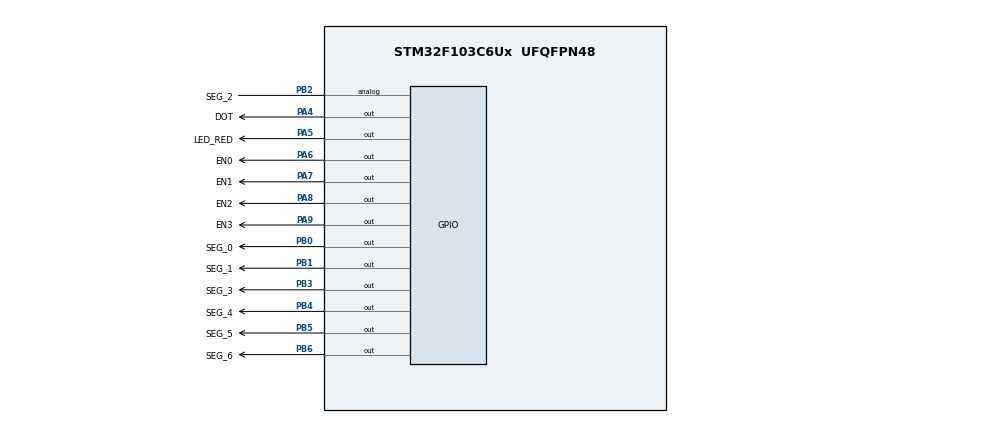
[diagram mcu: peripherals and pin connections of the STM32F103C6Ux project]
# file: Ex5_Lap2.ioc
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Mcu.Family=STM32F1
Mcu.Name=STM32F103C6Ux
Mcu.Package=UFQFPN48
NVIC.PriorityGroup=NVIC_PRIORITYGROUP_4
NVIC.TIM2_IRQn=true\:0\:0\:false\:false\:true\:true\:true
PA4.GPIO_Label=DOT
PA4.Signal=GPIO_Output
PA5.GPIO_Label=LED_RED
PA5.Signal=GPIO_Output
PA6.GPIO_Label=EN0
PA6.Signal=GPIO_Output
PA7.GPIO_Label=EN1
PA7.Signal=GPIO_Output
PA8.GPIO_Label=EN2
PA8.Signal=GPIO_Output
PA9.GPIO_Label=EN3
PA9.Signal=GPIO_Output
PB0.GPIO_Label=SEG_0
PB0.Signal=GPIO_Output
PB1.GPIO_Label=SEG_1
PB1.Signal=GPIO_Output
PB2.GPIO_Label=SEG_2
PB2.Signal=GPIO_Analog
PB3.GPIO_Label=SEG_3
PB3.Signal=GPIO_Output
PB4.GPIO_Label=SEG_4
PB4.Signal=GPIO_Output
PB5.GPIO_Label=SEG_5
PB5.Signal=GPIO_Output
PB6.GPIO_Label=SEG_6
PB6.Signal=GPIO_Output
ProjectManager.HeapSize=0x200
ProjectManager.StackSize=0x400
ProjectManager.TargetToolchain=STM32CubeIDE
RCC.APB1Freq_Value=8000000
RCC.APB2Freq_Value=8000000
TIM2.Period=9
TIM2.Prescaler=7999
VP_SYS_VS_ND.Mode=No_Debug
VP_TIM2_VS_ClockSourceINT.Mode=Internal
board=custom

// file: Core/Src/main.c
/* USER CODE BEGIN Header */
/**
  ******************************************************************************
  * @file           : main.c
  * @brief          : Main program body
  ******************************************************************************
  * @attention
  *
  * <h2><center>&copy; Copyright (c) 2022 STMicroelectronics.
  * All rights reserved.</center></h2>
  *
  * This software component is licensed by ST under BSD 3-Clause license,
  * the "License"; You may not use this file except in compliance with the
  * License. You may obtain a copy of the License at:
  *                        opensource.org/licenses/BSD-3-Clause
  *
  ******************************************************************************
  */
/* USER CODE END Header */
#include "main.h"

TIM_HandleTypeDef htim2;

void SystemClock_Config(void);
static void MX_GPIO_Init(void);
static void MX_TIM2_Init(void);

int NUM[10][7]= {
	{0,0,0,0,0,0,1}, //0
	{1,0,0,1,1,1,1}, //1
	{0,0,1,0,0,1,0}, //2
	{0,0,0,0,1,1,0}, //3
	{1,0,0,1,1,0,0}, //4
	{0,1,0,0,1,0,0}, //5
	{0,1,0,0,0,0,0}, //6
	{0,0,0,1,1,1,1}, //7
	{0,0,0,0,0,0,0}, //8
	{0,0,0,0,1,0,0}  //9
};
void display7SEG(int num){
	HAL_GPIO_WritePin(SEG_0_GPIO_Port, SEG_0_Pin, NUM[num][0] );// tin hieu thanh 0
	HAL_GPIO_WritePin(SEG_1_GPIO_Port, SEG_1_Pin, NUM[num][1] );// tin hieu thanh 1
	HAL_GPIO_WritePin(SEG_2_GPIO_Port, SEG_2_Pin, NUM[num][2] );// tin hieu thanh 2
	HAL_GPIO_WritePin(SEG_3_GPIO_Port, SEG_3_Pin, NUM[num][3] );// tin hieu thanh 3
	HAL_GPIO_WritePin(SEG_4_GPIO_Port, SEG_4_Pin, NUM[num][4] );// tin hieu thanh 4
	HAL_GPIO_WritePin(SEG_5_GPIO_Port, SEG_5_Pin, NUM[num][5] );// tin hieu thanh 5
	HAL_GPIO_WritePin(SEG_6_GPIO_Port, SEG_6_Pin, NUM[num][6] );// tin hieu thanh 6
}

int counter = 25;
const int MAX_LED = 4;
int index_led = 0;
int led_buffer [4] = {1 , 2 , 3 , 4};

void updateClockBuffer(int hour, int minute){
 	// update hour
 	if(hour < 10){
 		led_buffer[0]= 0;
 		led_buffer[1]= hour;
 	}
 	else if(hour < 20 && hour>10){
 		led_buffer[0]= 1;
 		led_buffer[1]= hour%10;
 	}
 	else{
 	    led_buffer[0]= 2;
 		led_buffer[1]= hour%20;
 	}
 	// update minute
 	if(minute<10){
 		led_buffer[2]= 0;
 		led_buffer[3]= minute;
 	}
 	else if(minute>=10&& minute<20){
 		led_buffer[2]= 1;
 		led_buffer[3]= minute%10;
 	}
 	else if(minute>=20&& minute<30){
 		led_buffer[2]= 2;
 		led_buffer[3]= minute%20;
 	}
 	else if(minute>=30&& minute<40){
 		led_buffer[2]= 3;
 		led_buffer[3]=  minute%30;
 	}
 	else if(minute>=40&& minute<50){
 		led_buffer[2]= 4;
 		led_buffer[3]= minute%40;
 	}
 	else if(minute>=50&& minute<60){
 		led_buffer[2]= 5;
 		led_buffer[3]= minute%50;
 	}
 	else{
 		led_buffer[2]= 6;
 		led_buffer[3]= 0;
 	}
 }
void led_on(int index_led){
switch( index_led){
		case 0:
			HAL_GPIO_WritePin(EN0_GPIO_Port, EN0_Pin, RESET);
			HAL_GPIO_WritePin(EN1_GPIO_Port, EN1_Pin, SET);
			HAL_GPIO_WritePin(EN2_GPIO_Port, EN2_Pin, SET);
			HAL_GPIO_WritePin(EN3_GPIO_Port, EN3_Pin, SET);
		break;

		case 1:
			HAL_GPIO_WritePin(EN0_GPIO_Port, EN0_Pin, SET);
			HAL_GPIO_WritePin(EN1_GPIO_Port, EN1_Pin, RESET);
			HAL_GPIO_WritePin(EN2_GPIO_Port, EN2_Pin, SET);
			HAL_GPIO_WritePin(EN3_GPIO_Port, EN3_Pin, SET);
		break;

		case 2:
			HAL_GPIO_WritePin(EN0_GPIO_Port, EN0_Pin, SET);
			HAL_GPIO_WritePin(EN1_GPIO_Port, EN1_Pin, SET);
			HAL_GPIO_WritePin(EN2_GPIO_Port, EN2_Pin, RESET);
			HAL_GPIO_WritePin(EN3_GPIO_Port, EN3_Pin, SET);
		break;

		case 3:
			HAL_GPIO_WritePin(EN0_GPIO_Port, EN0_Pin, SET);
			HAL_GPIO_WritePin(EN1_GPIO_Port, EN1_Pin, SET);
			HAL_GPIO_WritePin(EN2_GPIO_Port, EN2_Pin, SET);
			HAL_GPIO_WritePin(EN3_GPIO_Port, EN3_Pin, RESET);
		break;
	}
}
void update7SEG ( int index_led) {
switch ( index_led ) {
		case 0:
		// Display the first 7 SEG
			led_on(0);
			display7SEG(led_buffer[0]);
		break ;
		case 1:
		// Display the second 7 SEG
			led_on(1);
			display7SEG(led_buffer[1]);
		break ;
		case 2:
		// Display the third 7 SEG
			led_on(2);
			display7SEG(led_buffer[2]);
		break ;
		case 3:
		// Display the forth 7 SEG
			led_on(3);
			display7SEG(led_buffer[3]);
		break ;
		default :
		break ;
}
}

TIM_HandleTypeDef htim2;

int main(void)
{

  /* MCU Configuration--------------------------------------------------------*/

  /* Reset of all peripherals, Initializes the Flash interface and the Systick. */
  HAL_Init();

  /* Configure the system clock */
  SystemClock_Config();

  /* Initialize all configured peripherals */
  MX_GPIO_Init();
  MX_TIM2_Init();
  HAL_TIM_Base_Start_IT (& htim2 ) ;

  /* Infinite loop */
  /* USER CODE BEGIN WHILE */
  	int hour = 15 , minute = 8 , second = 50;
    while (1)
    {
    /* USER CODE END WHILE */
    	 second ++;
    		   if ( second >= 60) {
    			   second = 0;
    			   minute++;
    		   }
    		   if( minute >= 60) {
    			   minute = 0;
    			   hour++;
    		   }
    		   if( hour >=24) {
    			   hour = 0;
    		   }
    		   updateClockBuffer(hour, minute);
    		   HAL_Delay (1000);
  }
}

void SystemClock_Config(void)
{
  RCC_OscInitTypeDef RCC_OscInitStruct = {0};
  RCC_ClkInitTypeDef RCC_ClkInitStruct = {0};

  /** Initializes the RCC Oscillators according to the specified parameters
  * in the RCC_OscInitTypeDef structure.
  */
  RCC_OscInitStruct.OscillatorType = RCC_OSCILLATORTYPE_HSI;
  RCC_OscInitStruct.HSIState = RCC_HSI_ON;
  RCC_OscInitStruct.HSICalibrationValue = RCC_HSICALIBRATION_DEFAULT;
  RCC_OscInitStruct.PLL.PLLState = RCC_PLL_NONE;
  if (HAL_RCC_OscConfig(&RCC_OscInitStruct) != HAL_OK)
  {
    Error_Handler();
  }
  /** Initializes the CPU, AHB and APB buses clocks
  */
  RCC_ClkInitStruct.ClockType = RCC_CLOCKTYPE_HCLK|RCC_CLOCKTYPE_SYSCLK
                              |RCC_CLOCKTYPE_PCLK1|RCC_CLOCKTYPE_PCLK2;
  RCC_ClkInitStruct.SYSCLKSource = RCC_SYSCLKSOURCE_HSI;
  RCC_ClkInitStruct.AHBCLKDivider = RCC_SYSCLK_DIV1;
  RCC_ClkInitStruct.APB1CLKDivider = RCC_HCLK_DIV1;
  RCC_ClkInitStruct.APB2CLKDivider = RCC_HCLK_DIV1;

  if (HAL_RCC_ClockConfig(&RCC_ClkInitStruct, FLASH_LATENCY_0) != HAL_OK)
  {
    Error_Handler();
  }
}

static void MX_TIM2_Init(void)
{

  TIM_ClockConfigTypeDef sClockSourceConfig = {0};
  TIM_MasterConfigTypeDef sMasterConfig = {0};

  htim2.Instance = TIM2;
  htim2.Init.Prescaler = 7999;
  htim2.Init.CounterMode = TIM_COUNTERMODE_UP;
  htim2.Init.Period = 9;
  htim2.Init.ClockDivision = TIM_CLOCKDIVISION_DIV1;
  htim2.Init.AutoReloadPreload = TIM_AUTORELOAD_PRELOAD_DISABLE;
  if (HAL_TIM_Base_Init(&htim2) != HAL_OK)
  {
    Error_Handler();
  }
  sClockSourceConfig.ClockSource = TIM_CLOCKSOURCE_INTERNAL;
  if (HAL_TIM_ConfigClockSource(&htim2, &sClockSourceConfig) != HAL_OK)
  {
    Error_Handler();
  }
  sMasterConfig.MasterOutputTrigger = TIM_TRGO_RESET;
  sMasterConfig.MasterSlaveMode = TIM_MASTERSLAVEMODE_DISABLE;
  if (HAL_TIMEx_MasterConfigSynchronization(&htim2, &sMasterConfig) != HAL_OK)
  {
    Error_Handler();
  }

}

static void MX_GPIO_Init(void)
{
  GPIO_InitTypeDef GPIO_InitStruct = {0};

  /* GPIO Ports Clock Enable */
  __HAL_RCC_GPIOA_CLK_ENABLE();
  __HAL_RCC_GPIOB_CLK_ENABLE();

  /*Configure GPIO pin Output Level */
  HAL_GPIO_WritePin(GPIOA, DOT_Pin|LED_RED_Pin|EN0_Pin|EN1_Pin
                          |EN2_Pin|EN3_Pin, GPIO_PIN_RESET);

  /*Configure GPIO pin Output Level */
  HAL_GPIO_WritePin(GPIOB, SEG_0_Pin|SEG_1_Pin|SEG_3_Pin|SEG_4_Pin
                          |SEG_5_Pin|SEG_6_Pin, GPIO_PIN_RESET);

  /*Configure GPIO pins : DOT_Pin LED_RED_Pin EN0_Pin EN1_Pin
                           EN2_Pin EN3_Pin */
  GPIO_InitStruct.Pin = DOT_Pin|LED_RED_Pin|EN0_Pin|EN1_Pin
                          |EN2_Pin|EN3_Pin;
  GPIO_InitStruct.Mode = GPIO_MODE_OUTPUT_PP;
  GPIO_InitStruct.Pull = GPIO_NOPULL;
  GPIO_InitStruct.Speed = GPIO_SPEED_FREQ_LOW;
  HAL_GPIO_Init(GPIOA, &GPIO_InitStruct);

  /*Configure GPIO pins : SEG_0_Pin SEG_1_Pin SEG_3_Pin SEG_4_Pin
                           SEG_5_Pin SEG_6_Pin */
  GPIO_InitStruct.Pin = SEG_0_Pin|SEG_1_Pin|SEG_3_Pin|SEG_4_Pin
                          |SEG_5_Pin|SEG_6_Pin;
  GPIO_InitStruct.Mode = GPIO_MODE_OUTPUT_PP;
  GPIO_InitStruct.Pull = GPIO_NOPULL;
  GPIO_InitStruct.Speed = GPIO_SPEED_FREQ_LOW;
  HAL_GPIO_Init(GPIOB, &GPIO_InitStruct);

  /*Configure GPIO pin : SEG_2_Pin */
  GPIO_InitStruct.Pin = SEG_2_Pin;
  GPIO_InitStruct.Mode = GPIO_MODE_ANALOG;
  HAL_GPIO_Init(SEG_2_GPIO_Port, &GPIO_InitStruct);

}

/* USER CODE BEGIN 4 */

 void HAL_TIM_PeriodElapsedCallback ( TIM_HandleTypeDef * htim ){
	counter--;
	if(counter <= 0){
		counter = 25;
		update7SEG(index_led);
		index_led++;
	}
	if(index_led > MAX_LED){
		index_led= 0;
	}
}

/* USER CODE END 4 */

void Error_Handler(void)
{
  __disable_irq();
  while (1)
  {
  }
}

/************************ (C) COPYRIGHT STMicroelectronics *****END OF FILE****/
